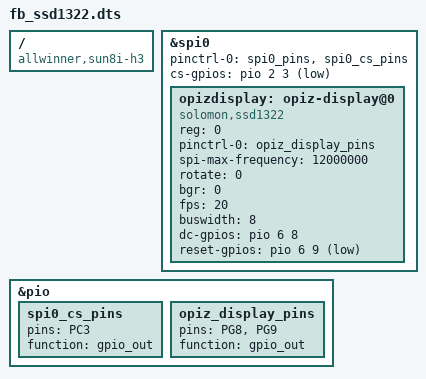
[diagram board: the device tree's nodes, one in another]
/dts-v1/;
/plugin/;
/ {
        compatible = "allwinner,sun8i-h3";

        fragment@0 {
                target = <&spi0>;
                __overlay__ {
                        status = "okay";
                };
        };

        fragment@1 {
                target = <&pio>;
                __overlay__ {
                        spi0_cs_pins: spi0_cs_pins {
                                pins = "PC3";
                                function = "gpio_out";
                        };

                        opiz_display_pins: opiz_display_pins {
                                pins = "PG8", "PG9"; 
                                function = "gpio_out";
                        };
                };
        };

        fragment@2 {
                target = <&spi0>;
                __overlay__ {
                        /* needed to avoid dtc warning */
                        #address-cells = <1>;
                        #size-cells = <0>;
                        pinctrl-0=<&spi0_pins &spi0_cs_pins>;
                        cs-gpios=<&pio 2 3 1>;

                        opizdisplay: opiz-display@0{
                                compatible = "solomon,ssd1322";
                                reg = <0>;  /* Chip Select 0 */
                                pinctrl-names = "default";
                                pinctrl-0 = <&opiz_display_pins>;

                                spi-max-frequency = <12000000>;
                                rotate = <0>;
                                bgr = <0>;
                                fps = <20>;
                                buswidth = <8>;
                                dc-gpios = <&pio 6 8 0>;     /* PIN_16  GPIOG8 */
                                reset-gpios = <&pio 6 9 1 >; /* PIN_18  GPIOG9 */ 
                                status="okay";
                        };
                };
        };
};

